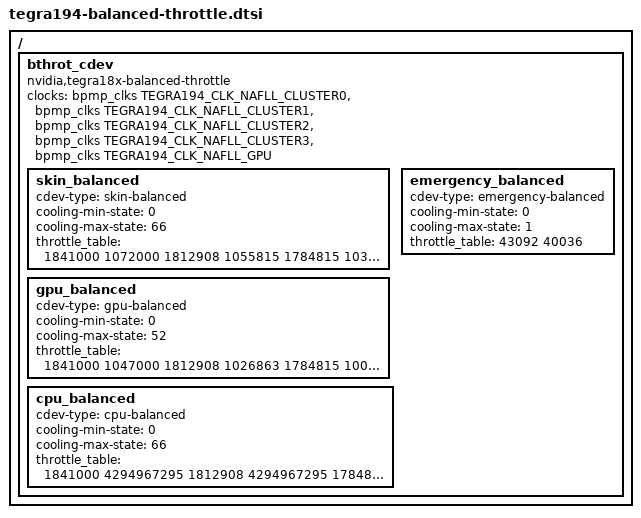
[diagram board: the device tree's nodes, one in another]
/*
 * Copyright (c) 2018, NVIDIA CORPORATION.  All rights reserved.
 *
 * This program is free software; you can redistribute it and/or modify
 * it under the terms of the GNU General Public License as published by
 * the Free Software Foundation; version 2 of the License.
 *
 * This program is distributed in the hope that it will be useful, but WITHOUT
 * ANY WARRANTY; without even the implied warranty of MERCHANTABILITY or
 * FITNESS FOR A PARTICULAR PURPOSE.  See the GNU General Public License for
 * more details.
 *
 * You should have received a copy of the GNU General Public License along
 * with this program; if not, write to the Free Software Foundation, Inc.,
 * 51 Franklin Street, Fifth Floor, Boston, MA  02110-1301, USA.
 *
 */

/{
	bthrot_cdev {
		compatible = "nvidia,tegra18x-balanced-throttle";
		clocks = <&bpmp_clks TEGRA194_CLK_NAFLL_CLUSTER0>,
				<&bpmp_clks TEGRA194_CLK_NAFLL_CLUSTER1>,
				<&bpmp_clks TEGRA194_CLK_NAFLL_CLUSTER2>,
				<&bpmp_clks TEGRA194_CLK_NAFLL_CLUSTER3>,
				<&bpmp_clks TEGRA194_CLK_NAFLL_GPU>;
		clock-names = "mcpu", "gpu";
		skin_balanced {
			cdev-type = "skin-balanced";
			cooling-min-state = <0>;
			cooling-max-state = <66>;
			#cooling-cells = <2>;
			throttle_table = <
			1841000	1072000
			1812908	1055815
			1784815	1039631
			1756723	1023446
			1728631	1007262
			1700538	991077
			1672446	974892
			1644354	958708
			1616262	942523
			1588169	926338
			1560077	910154
			1531985	893969
			1503892	877785
			1475800	861600
			1447708	845415
			1419615	829231
			1391523	813046
			1363431	796862
			1335338	780677
			1307246	764492
			1279154	748308
			1251062	732123
			1222969	715938
			1194877	699754
			1166785	683569
			1138692	667385
			1110600	651200
			1082508	635015
			1054415	618831
			1026323	602646
			998231	586462
			970138	570277
			942046	554092
			913954	537908
			885862	521723
			857769	505538
			829677	489354
			801585	473169
			773492	456985
			745400	440800
			717308	424615
			689215	408431
			661123	392246
			633031	376062
			604938	359877
			576846	343692
			548754	327508
			520662	311323
			492569	295138
			464477	278954
			436385	262769
			408292	246585
			380200	230400
			352108	214215
			324015	198031
			295923	181846
			267831	165662
			239738	149477
			211646	133292
			183554	117108
			155462	100923
			127369	84738
			99277	68554
			71185	52369
			43092	36185
			15000	20000
			>;
		};
		gpu_balanced {
			cdev-type = "gpu-balanced";
			cooling-min-state = <0>;
			cooling-max-state = <52>;
			#cooling-cells = <2>;
			throttle_table = <
			1841000	1047000
			1812908	1026863
			1784815	1006725
			1756723	986588
			1728631	966451
			1700538	946314
			1672446	926176
			1644354	906039
			1616262	885902
			1588169	865765
			1560077	845627
			1531985	825490
			1503892	805353
			1475800	785216
			1447708	765078
			1419615	744941
			1391523	724804
			1363431	704667
			1335338	684529
			1307246	664392
			1279154	644255
			1251062	624118
			1222969	603980
			1194877	583843
			1166785	563706
			1138692	543569
			1110600	523431
			1082508	503294
			1054415	483157
			1026323	463020
			998231	442882
			970138	422745
			942046	402608
			913954	382471
			885862	362333
			857769	342196
			829677	322059
			801585	301922
			773492	281784
			745400	261647
			717308	241510
			689215	221373
			661123	201235
			633031	181098
			604938	160961
			576846	140824
			548754	120686
			520662	100549
			492569	80412
			464477	60275
			436385	40137
			408292	10000
			>;
		};

		cpu_balanced {
			cdev-type = "cpu-balanced";
			cooling-min-state = <0>;
			cooling-max-state = <66>;
			#cooling-cells = <2>;
			throttle_table = <
			1841000	4294967295
			1812908	4294967295
			1784815	4294967295
			1756723	4294967295
			1728631	4294967295
			1700538	4294967295
			1672446	4294967295
			1644354	4294967295
			1616262	4294967295
			1588169	4294967295
			1560077	1122000
			1531985	1101964
			1503892	1081927
			1475800	1061891
			1447708	1041855
			1419615	1021818
			1391523	1001782
			1363431	981745
			1335338	961709
			1307246	941673
			1279154	921636
			1251062	901600
			1222969	881564
			1194877	861527
			1166785	841491
			1138692	821455
			1110600	801418
			1082508	781382
			1054415	761345
			1026323	741309
			998231	721273
			970138	701236
			942046	681200
			913954	661164
			885862	641127
			857769	621091
			829677	601055
			801585	581018
			773492	560982
			745400	540945
			717308	520909
			689215	500873
			661123	480836
			633031	460800
			604938	440764
			576846	420727
			548754	400691
			520662	380655
			492569	360618
			464477	340582
			436385	320545
			408292	300509
			380200	280473
			352108	260436
			324015	240400
			295923	220364
			267831	200327
			239738	180291
			211646	160255
			183554	140218
			155462	120182
			127369	100145
			99277	80109
			71185	60073
			43092	40036
			15000	20000>;
		};
		emergency_balanced {
			cdev-type = "emergency-balanced";
			cooling-min-state = <0>;
			cooling-max-state = <1>;
			#cooling-cells = <2>;
			throttle_table = <
			43092	40036
			>;
		};
	};
};
